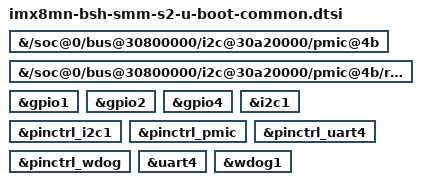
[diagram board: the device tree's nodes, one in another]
// SPDX-License-Identifier: GPL-2.0+
/*
 * Copyright 2021 Collabora Ltd.
 * Copyright 2021 BSH Hausgeraete GmbH
 */

#include "imx8mn-u-boot.dtsi"

&{/soc@0/bus@30800000/i2c@30a20000/pmic@4b} {
	bootph-pre-ram;
};

&{/soc@0/bus@30800000/i2c@30a20000/pmic@4b/regulators} {
	bootph-pre-ram;
};

&gpio1 {
	bootph-pre-ram;
};

&gpio2 {
	bootph-pre-ram;
};

&gpio4 {
	bootph-pre-ram;
};

&i2c1 {
	bootph-pre-ram;
};

&pinctrl_i2c1 {
	bootph-pre-ram;
};

&pinctrl_pmic {
	bootph-pre-ram;
};

&pinctrl_uart4 {
	bootph-pre-ram;
};

&pinctrl_wdog {
	bootph-pre-ram;
};

&uart4 {
	bootph-pre-ram;
};

&wdog1 {
	bootph-pre-ram;
};
